# MDR1986BE3T register map
Vendor: Milandr; File version: 1.0
CPU: CM1 r0p0, little endian, no MPU, no FPU, 3 interrupt priority bits
Registers are 32-bit, read-write, reset 0x0 unless marked. A register's access mark holds for its fields unless they carry their own. Offsets are from the block's base; [hi:lo] are bit positions; {n}, {i} and the like mark numbered series.

## MDR_EBC — EBC
Base 0x400F0000; register names take the prefix MDR_EBC_
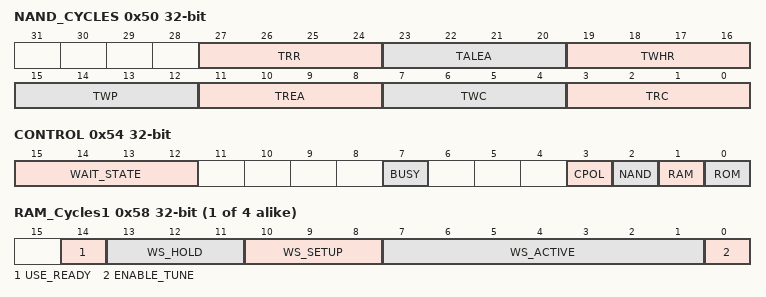
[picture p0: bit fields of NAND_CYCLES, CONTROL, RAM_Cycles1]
0x50 NAND_CYCLES — EBC NAND Timing Register
  [27:24] TRR, [23:20] TALEA, [19:16] TWHR, [15:12] TWP, [11:8] TREA, [7:4] TWC, [3:0] TRC
0x54 CONTROL — EBC Control Register
  [15:12] WAIT_STATE, [7] BUSY, [3] CPOL, [2] NAND, [1] RAM, [0] ROM
{0x54+4i} RAM_Cycles{i} (i=1..4)
  [14] USE_READY, [13:11] WS_HOLD, [10:8] WS_SETUP, [7:1] WS_ACTIVE, [0] ENABLE_TUNE

## MDR_AUDIO_IP — AUDIO_IP
Base 0x40100000; register names take the prefix MDR_AUDIO_IP_
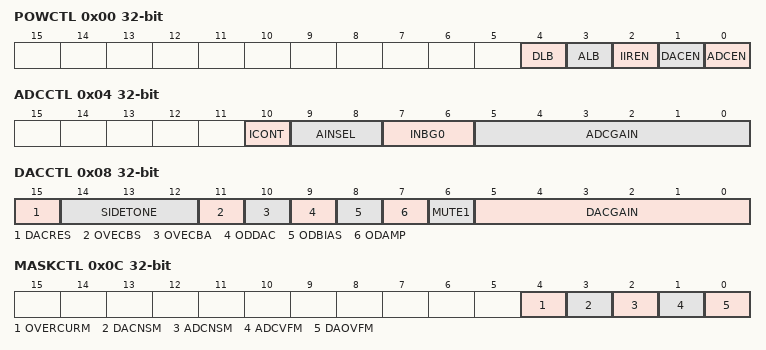
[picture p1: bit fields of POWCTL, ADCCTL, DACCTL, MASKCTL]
0x00 POWCTL — AUDIO control register
  [4] DLB, [3] ALB, [2] IIREN, [1] DACEN, [0] ADCEN
0x04 ADCCTL — ADC control register
  [10] ICONT, [9:8] AINSEL, [7:6] INBG0, [5:0] ADCGAIN
0x08 DACCTL — DAC control register
  [15] DACRES, [14:12] SIDETONE, [11] OVECBS, [10] OVECBA, [9] ODDAC, [8] ODBIAS, [7] ODAMP, [6] MUTE1, [5:0] DACGAIN
0x0C MASKCTL — IRQ mask register
  [4] OVERCURM, [3] DACNSM, [2] ADCNSM, [1] ADCVFM, [0] DAOVFM
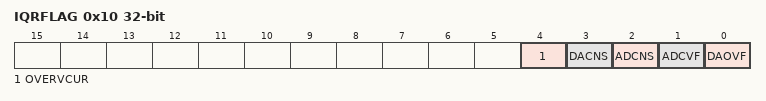
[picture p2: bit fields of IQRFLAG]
0x10 IQRFLAG — IRQ flag register
  [4] OVERVCUR, [3] DACNS, [2] ADCNS, [1] ADCVF, [0] DAOVF
0x14 ADCREG — ADC FIFO register
  [15:0] ADCSMP
0x18 DACREG — DAC FIFO register
  [15:0] DACSMP

## MDR_LED — LED
Base 0x40108000; register names take the prefix MDR_LED_
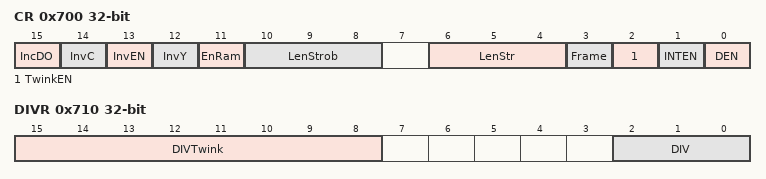
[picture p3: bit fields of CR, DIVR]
0x700 CR — LED status register
  [15] IncDO, [14] InvC, [13] InvEN, [12] InvY, [11] EnRam, [10:8] LenStrob, [6:4] LenStr, [3] Frame, [2] TwinkEN, [1] INTEN, [0] DEN
0x704 Jark — LED jark register
  [7:0] Jark
0x710 DIVR — LED DIV register
  [15:8] DIVTwink, [2:0] DIV
0x714 SR — lED status register
  [0] WRReady

## MDR_KEYPAD — KEYPAD
Base 0x40110000; register names take the prefix MDR_KEYPAD_
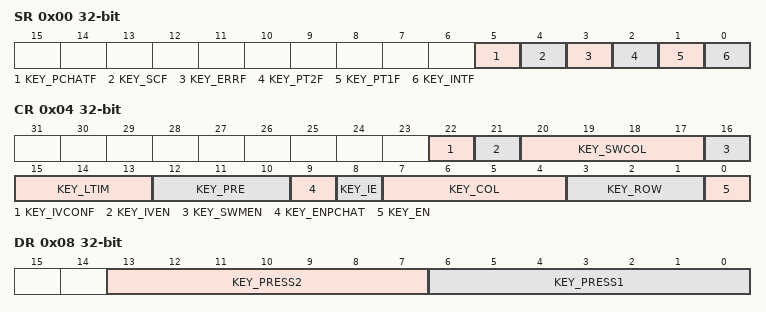
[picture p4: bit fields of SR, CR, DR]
0x00 SR — KEYPAD status register
  [5] KEY_PCHATF, [4] KEY_SCF, [3] KEY_ERRF, [2] KEY_PT2F, [1] KEY_PT1F, [0] KEY_INTF
0x04 CR — KEYPAD contril register
  [22] KEY_IVCONF, [21] KEY_IVEN, [20:17] KEY_SWCOL, [16] KEY_SWMEN, [15:13] KEY_LTIM, [12:10] KEY_PRE, [9] KEY_ENPCHAT, [8] KEY_IE, [7:4] KEY_COL, [3:1] KEY_ROW, [0] KEY_EN
0x08 DR — KEYPAD data register
  [13:7] KEY_PRESS2, [6:0] KEY_PRESS1
{0x8+4i} SWR{i} (i=1..4) — KEYPAD SWR{i} status register
  [31:0] KEY_SWR{i}

## MDR_ETH1 — Ethernet1
Base 0x30000000; register names take the prefix MDR_ETH1_
Same registers: MDR_ETH2 0x34000000 (register names take the prefix MDR_ETH2_)
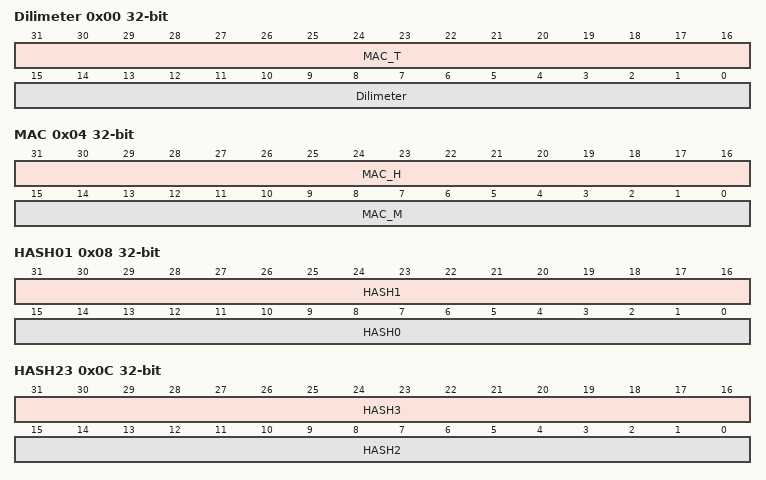
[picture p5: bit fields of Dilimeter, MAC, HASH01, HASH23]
0x00 Dilimeter
  [31:16] MAC_T, [15:0] Dilimeter
0x04 MAC
  [31:16] MAC_H, [15:0] MAC_M
0x08 HASH01
  [31:16] HASH1, [15:0] HASH0
0x0C HASH23
  [31:16] HASH3, [15:0] HASH2
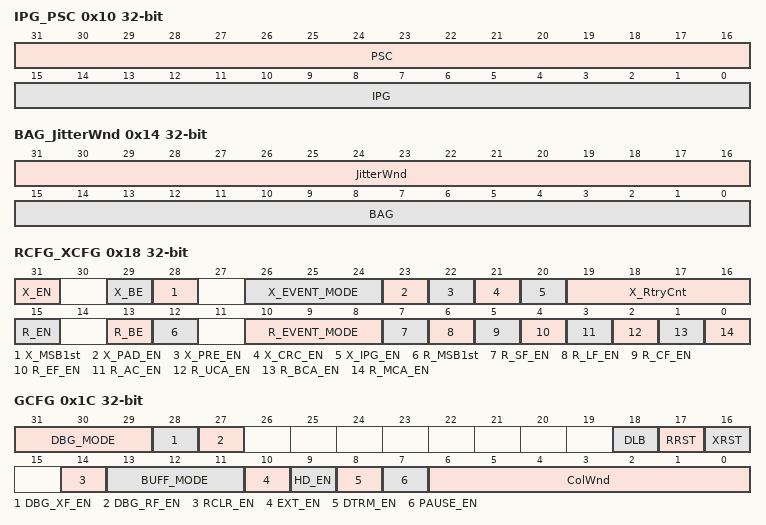
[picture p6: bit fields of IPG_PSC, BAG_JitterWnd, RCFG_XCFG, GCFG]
0x10 IPG_PSC
  [31:16] PSC, [15:0] IPG
0x14 BAG_JitterWnd
  [31:16] JitterWnd, [15:0] BAG
0x18 RCFG_XCFG
  [31] X_EN, [29] X_BE, [28] X_MSB1st, [26:24] X_EVENT_MODE, [23] X_PAD_EN, [22] X_PRE_EN, [21] X_CRC_EN, [20] X_IPG_EN, [19:16] X_RtryCnt, [15] R_EN, [13] R_BE, [12] R_MSB1st, [10:8] R_EVENT_MODE, [7] R_SF_EN, [6] R_LF_EN, [5] R_CF_EN, [4] R_EF_EN, [3] R_AC_EN, [2] R_UCA_EN, [1] R_BCA_EN, [0] R_MCA_EN
0x1C GCFG
  [31:29] DBG_MODE, [28] DBG_XF_EN, [27] DBG_RF_EN, [18] DLB, [17] RRST, [16] XRST, [14] RCLR_EN, [13:11] BUFF_MODE, [10] EXT_EN, [9] HD_EN, [8] DTRM_EN, [7] PAUSE_EN, [6:0] ColWnd
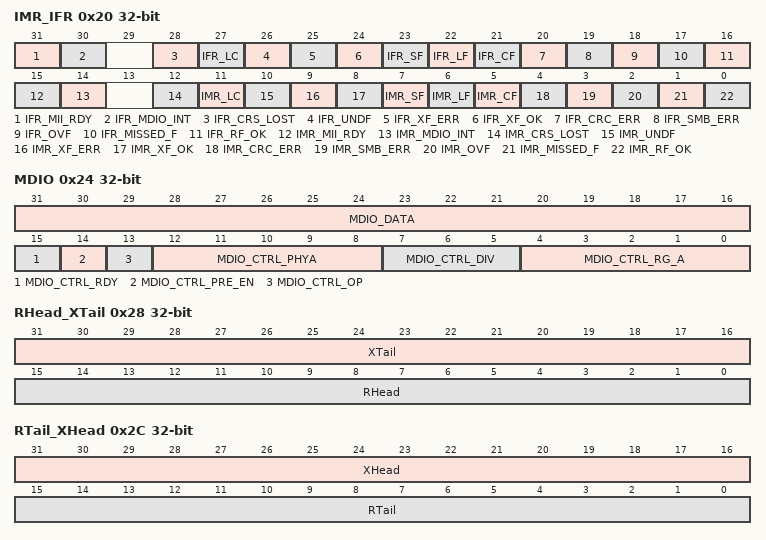
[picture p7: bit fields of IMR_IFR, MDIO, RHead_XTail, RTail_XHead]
0x20 IMR_IFR
  [31] IFR_MII_RDY, [30] IFR_MDIO_INT, [28] IFR_CRS_LOST, [27] IFR_LC, [26] IFR_UNDF, [25] IFR_XF_ERR, [24] IFR_XF_OK, [23] IFR_SF, [22] IFR_LF, [21] IFR_CF, [20] IFR_CRC_ERR, [19] IFR_SMB_ERR, [18] IFR_OVF, [17] IFR_MISSED_F, [16] IFR_RF_OK, [15] IMR_MII_RDY, [14] IMR_MDIO_INT, [12] IMR_CRS_LOST, [11] IMR_LC, [10] IMR_UNDF, [9] IMR_XF_ERR, [8] IMR_XF_OK, [7] IMR_SF, [6] IMR_LF, [5] IMR_CF, [4] IMR_CRC_ERR, [3] IMR_SMB_ERR, [2] IMR_OVF, [1] IMR_MISSED_F, [0] IMR_RF_OK
0x24 MDIO
  [31:16] MDIO_DATA, [15] MDIO_CTRL_RDY, [14] MDIO_CTRL_PRE_EN, [13] MDIO_CTRL_OP, [12:8] MDIO_CTRL_PHYA, [7:5] MDIO_CTRL_DIV, [4:0] MDIO_CTRL_RG_A
0x28 RHead_XTail
  [31:16] XTail, [15:0] RHead
0x2C RTail_XHead
  [31:16] XHead, [15:0] RTail
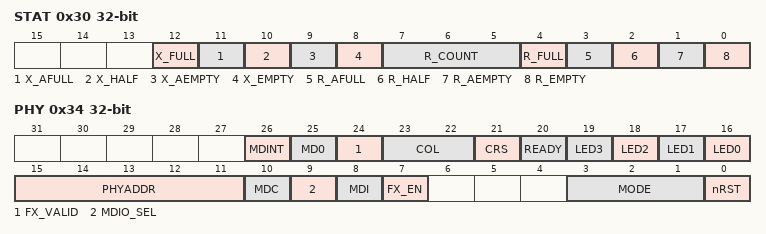
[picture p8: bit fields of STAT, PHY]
0x30 STAT
  [12] X_FULL, [11] X_AFULL, [10] X_HALF, [9] X_AEMPTY, [8] X_EMPTY, [7:5] R_COUNT, [4] R_FULL, [3] R_AFULL, [2] R_HALF, [1] R_AEMPTY, [0] R_EMPTY
0x34 PHY
  [26] MDINT, [25] MD0, [24] FX_VALID, [23:22] COL, [21] CRS, [20] READY, [n+16] LED{n} (n=0..3), [15:11] PHYADDR, [10] MDC, [9] MDIO_SEL, [8] MDI, [7] FX_EN, [3:1] MODE, [0] nRST
